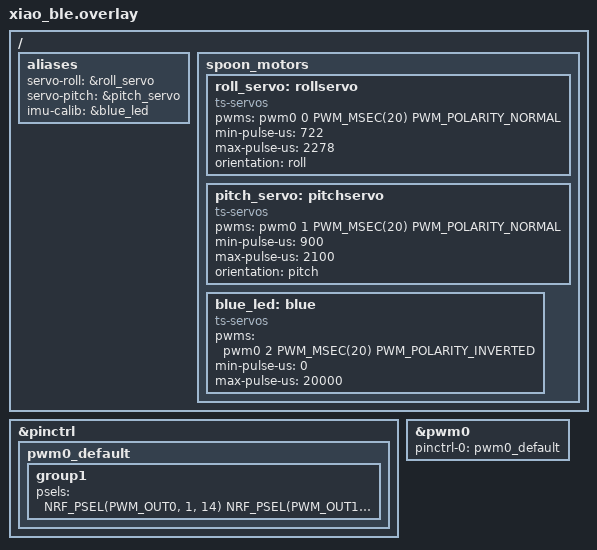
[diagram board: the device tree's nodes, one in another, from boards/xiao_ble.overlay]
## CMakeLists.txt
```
# SPDX-License-Identifier: Apache-2.0

cmake_minimum_required(VERSION 3.20.0)
find_package(Zephyr REQUIRED HINTS $ENV{ZEPHYR_BASE})
project(tremosense)

FILE(GLOB app_sources src/*.c)
target_sources(app PRIVATE ${app_sources})
target_include_directories(app PRIVATE include)
```

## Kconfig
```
source "Kconfig.zephyr"

config IMU_CALIBRATION_WHILE_TESTING
        bool "Enable calibration  of IMU at boot"
        default n
        help
                If enabled, the IMU collects 300 samples over span of 3 seconds 
                and averages values for all 6 measurments (accelerometer and 
                gyroscope in x,y,z axes)

config PWM_TEST_RB_LED
        bool "Enable PWM test for RB LED"
        default n
        help
                If enabled, the RB LED will be used for testing PWM feature. 
                Green LED indicates Roll Servo motor and Red LED indicates Pitch 
                Servo motor.

config CLEAR_SCREEN
        bool "Clear screen before printing next values"
        default n
        help
                If enabled, the console screen will be cleared before printing 
                upcoming IMU, EKK and servo values.
```

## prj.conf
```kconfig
CONFIG_STDOUT_CONSOLE=y
CONFIG_I2C=y
CONFIG_SPI=y
CONFIG_SENSOR=y
CONFIG_LSM6DSL_TRIGGER_GLOBAL_THREAD=y
CONFIG_CBPRINTF_FP_SUPPORT=y
CONFIG_LOG=y
CONFIG_LOG_MODE_DEFERRED=y
CONFIG_CBPRINTF_FP_SUPPORT=y
```

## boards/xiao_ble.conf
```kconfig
CONFIG_PWM=y
CONFIG_PWM_NRFX=y

CONFIG_LOG=y
CONFIG_LOG_MODE_DEFERRED=y
CONFIG_LOG_FMT_SECTION=y
CONFIG_STDOUT_CONSOLE=y
CONFIG_CBPRINTF_FP_SUPPORT=y

CONFIG_I2C=y
CONFIG_SENSOR=y
CONFIG_LSM6DSL_TRIGGER_OWN_THREAD=y
CONFIG_IMU_CALIBRATION_WHILE_TESTING=y
CONFIG_CLEAR_SCREEN=n
```

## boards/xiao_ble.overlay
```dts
&pinctrl {
        pwm0_default: pwm0_default {
                group1 {
                        psels = <NRF_PSEL(PWM_OUT0, 1, 14)  // D9  - Roll servo
                                 NRF_PSEL(PWM_OUT1, 1, 15)  // D10 - Pitch Servo
                                 NRF_PSEL(PWM_OUT2, 0, 06)>; // IMU Calibration
                };
        };
};

&pwm0 {
	status = "okay";
        /delete-property/ pinctrl-1;
	pinctrl-0 = <&pwm0_default>;
	pinctrl-names = "default";
};

/ {
        aliases {
                servo-roll = &roll_servo;
                servo-pitch = &pitch_servo;
                imu-calib = &blue_led;
        };
        spoon_motors {
                roll_servo: rollservo {
                        compatible = "ts-servos";
                        pwms = <&pwm0 0 PWM_MSEC(20) PWM_POLARITY_NORMAL>;
                        min-pulse-us = <722>;
                        max-pulse-us = <2278>;
                        orientation = "roll";
                };
                pitch_servo: pitchservo {
                        compatible = "ts-servos";
                        pwms = <&pwm0 1 PWM_MSEC(20) PWM_POLARITY_NORMAL>;
                        min-pulse-us = <900>;
                        max-pulse-us = <2100>;
                        orientation = "pitch";
                };
                blue_led: blue {                        
                        compatible = "ts-servos";
                        pwms = <&pwm0 2 PWM_MSEC(20) PWM_POLARITY_INVERTED>;
                        min-pulse-us = <0>;
                        max-pulse-us = <20000>;
                };
        };
};
```

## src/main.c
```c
#include "imu.h"
#include "pwm.h"
#include "ekf.h"

LOG_MODULE_REGISTER(main, LOG_LEVEL_INF);

static struct k_thread imu_thread_data;
static struct k_thread pwm_thread_data;

k_tid_t imu_tid, pwm_tid;

K_THREAD_STACK_DEFINE(imu_thread_stack, IMU_THREAD_STACK_SIZE_BYTES);
K_THREAD_STACK_DEFINE(pwm_thread_stack, PWM_TASK_STACK_SIZE_BYTES);


int main(void)
{
	int err;

	const struct device *const lsm6ds3_trc_dev = DEVICE_DT_GET_ONE(st_lsm6dsl);
	err = imu_init(lsm6ds3_trc_dev);
	if (err) {
		LOG_ERR("Failed to initialize IMU: %d", err);
		return err;
	}


	ekf_init();	

	imu_tid = k_thread_create(&imu_thread_data, 
				  imu_thread_stack,
				  K_THREAD_STACK_SIZEOF(imu_thread_stack),
				  (k_thread_entry_t)imu_thread_function,
				  NULL, NULL, NULL,
				  K_PRIO_PREEMPT(1), 0, K_NO_WAIT);
	
	pwm_tid = k_thread_create(&pwm_thread_data, 
				  pwm_thread_stack,
				  K_THREAD_STACK_SIZEOF(pwm_thread_stack),
				  (k_thread_entry_t)pwm_thread_function,
				  NULL, NULL, NULL,
				  K_PRIO_PREEMPT(5), 0, K_NO_WAIT);


	return 0;
}
```

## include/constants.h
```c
#ifndef CONSTANTS_H
#define CONSTANTS_H

/* EKF process noise covariance (Q).
 * Represents uncertainty in the gyroscope-based prediction model.
 * Higher values increase reliance on accelerometer corrections.
 */
#define Q_GYRO_PROCESS_NOISE 0.0f

/* EKF measurement noise covariance (R).
 * Represents uncertainty in accelerometer angle measurements.
 * Higher values increase reliance on gyroscope integration.
 */
#define R_ACCEL_MEASUREMENT_NOISE 0.0f

/* LQR Controller Gain :
 * Row 0 -> Roll servo controller gains
 * Row 1 -> Pitch servo controller gains
 *
 * Column 0 -> Roll angle gain
 * Column 1 -> Roll angular velocity gain
 * Column 2 -> Pitch angle gain
 * Column 3 -> Pitch angular velocity gain
 */
static const float K_lqr[2][4] = {
    { 0.0f, 0.0f, 0.0f, 0.0f }, 
    { 0.0f, 0.0f, 0.0f, 0.0f }  
};

/* Limit pitch estimate to avoid Euler-angle singularities
 * (tan(), sec()) near ±90°.
 */
#define MAX_PITCH_RAD 0.0f

#endif /* CONSTANTS_H */
```

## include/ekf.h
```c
#ifndef EKF_H
#define EKF_H

#include <zephyr/logging/log.h>
#include "constants.h"

typedef struct {
    float roll; 
    float pitch;
} ekf_result_t;

extern ekf_result_t ekf_calculated_results;

#define RAD_TO_DEG 57.2957795f

void ekf_init(void);

void ekf_update(float ax, float ay, float az,
                float gx, float gy, float gz,
                float dt, float Q_val, float R_val,
                ekf_result_t *result);

#endif /* EKF_H */
```

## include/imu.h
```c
#ifndef IMU_H
#define IMU_H

#include <zephyr/kernel.h>
#include <zephyr/device.h>
#include <zephyr/logging/log.h>
#include <zephyr/drivers/sensor.h>
#include <zephyr/devicetree.h>

#define IMU_SLEEP_MS 50
#define IMU_THREAD_STACK_SIZE_BYTES 2048

extern k_tid_t imu_tid;

void lsm6ds3_trc_trigger_handler(const struct device *dev,
			     const struct sensor_trigger *trig);

int imu_init(const struct device *imu_dev);

void calibrate_imu(void);

int imu_readings(void);

void imu_thread_function(void *arg1, void *arg2, void *arg3);

#endif /* IMU_H */
```

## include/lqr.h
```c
#ifndef LQR_H
#define LQR_H

#include "constants.h"

#define DEG_TO_RAD 0.01745329f
#define RAD_TO_DEG 57.2957795f

void lqr_update(float phi_deg, float theta_deg, 
                float p_raw, float q_raw, 
                float bias_phi, float bias_theta, 
                float *u_roll_deg, float *u_pitch_deg);

#endif /* LQR_H */
```

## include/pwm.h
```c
#ifndef PWM_H
#define PWM_H

#include "lqr.h"

#include <zephyr/kernel.h>
#include <zephyr/drivers/pwm.h>
#include <zephyr/logging/log.h>

#include "lqr.h"

extern const struct pwm_dt_spec roll;
extern const struct pwm_dt_spec pitch;

extern float target_servo_roll_deg, target_servo_pitch_deg;

#define PWM_TASK_STACK_SIZE_BYTES 1024

#define PWM_SLEEP_MS 10 

extern k_tid_t pwm_tid;

int servos_reset(void);

int set_servo_angle(const struct pwm_dt_spec *pwm_dev_roll, 
                   const struct pwm_dt_spec *pwm_dev_pitch,
                   lqr_result_t *result);

int servo_sweep(const struct pwm_dt_spec *pwm_dev);

void pwm_thread_function(void *arg1, void *arg2, void *arg3);

#endif /* PWM_H */
```

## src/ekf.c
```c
#include "ekf.h"

/* EKF State Vector
 *
 * x[0] -> Roll angle  (phi)   [rad]
 * x[1] -> Pitch angle (theta) [rad]
 *
 * The EKF estimates drift-free roll and pitch angles by
 * fusing gyroscope angular rates with accelerometer measurements.
 */

static float x[2];      
static float P[2][2];  

ekf_result_t ekf_calculated_results;

void ekf_init(void)
{
    x[0] = 0.0f; x[1] = 0.0f;
    P[0][0] = 0.1f; P[0][1] = 0.0f;
    P[1][0] = 0.0f; P[1][1] = 0.1f;
}

void ekf_update(float ax, float ay, float az,
                float gx, float gy, float gz,
                float dt, float Q_val, float R_val,
                ekf_result_t *result)
{
    float p = gx, q = gy, r = gz;

    float phi   = x[0];
    float theta = x[1];

    float s_phi = sinf(phi);
    float c_phi = cosf(phi);
    float s_the = sinf(theta);
    float c_the = cosf(theta);
    float t_the = s_the / c_the;

    float sec_the = (fabsf(c_the) < 0.01f) ? 100.0f : (1.0f / c_the);

    // PREDICT -----------------------------------------------------------------
    float phi_dot   = p + q * s_phi * t_the + r * c_phi * t_the;
    float theta_dot = q * c_phi - r * s_phi;

    x[0] += phi_dot   * dt;
    x[1] += theta_dot * dt;

    float A11 =  q * c_phi * t_the - r * s_phi * t_the;
    float A12 = (q * s_phi + r * c_phi) * (sec_the * sec_the);
    float A21 = -q * s_phi - r * c_phi;

    float F[2][2];
    F[0][0] = 1.0f + A11 * dt;
    F[0][1] =        A12 * dt;
    F[1][0] =        A21 * dt;
    F[1][1] = 1.0f;             // A22=0

    float tmp[2][2];
    tmp[0][0] = F[0][0]*P[0][0] + F[0][1]*P[1][0];
    tmp[0][1] = F[0][0]*P[0][1] + F[0][1]*P[1][1];
    tmp[1][0] = F[1][0]*P[0][0] + F[1][1]*P[1][0];
    tmp[1][1] = F[1][0]*P[0][1] + F[1][1]*P[1][1];

    P[0][0] = tmp[0][0]*F[0][0] + tmp[0][1]*F[0][1] + Q_val;
    P[0][1] = tmp[0][0]*F[1][0] + tmp[0][1]*F[1][1];
    P[1][0] = tmp[1][0]*F[0][0] + tmp[1][1]*F[0][1];
    P[1][1] = tmp[1][0]*F[1][0] + tmp[1][1]*F[1][1] + Q_val;

    // UPDATE ------------------------------------------------------------------
    float accel_roll  = atan2f(ay, az);
    float accel_pitch = atan2f(-ax, sqrtf(ay*ay + az*az));

    float y0 = accel_roll  - x[0];
    float y1 = accel_pitch - x[1];

    float S[2][2];
    S[0][0] = P[0][0] + R_val;
    S[0][1] = P[0][1];
    S[1][0] = P[1][0];
    S[1][1] = P[1][1] + R_val;

    float det_S = S[0][0]*S[1][1] - S[0][1]*S[1][0];
    float inv_S[2][2];
    inv_S[0][0] =  S[1][1] / det_S;
    inv_S[0][1] = -S[0][1] / det_S;
    inv_S[1][0] = -S[1][0] / det_S;
    inv_S[1][1] =  S[0][0] / det_S;

    float K[2][2];
    K[0][0] = P[0][0]*inv_S[0][0] + P[0][1]*inv_S[1][0];
    K[0][1] = P[0][0]*inv_S[0][1] + P[0][1]*inv_S[1][1];
    K[1][0] = P[1][0]*inv_S[0][0] + P[1][1]*inv_S[1][0];
    K[1][1] = P[1][0]*inv_S[0][1] + P[1][1]*inv_S[1][1];

    x[0] += K[0][0]*y0 + K[0][1]*y1;
    x[1] += K[1][0]*y0 + K[1][1]*y1;

    float IK[2][2];
    IK[0][0] = 1.0f - K[0][0]; IK[0][1] = -K[0][1];
    IK[1][0] = -K[1][0];       IK[1][1] = 1.0f - K[1][1];

    float Pn[2][2];
    Pn[0][0] = IK[0][0]*P[0][0] + IK[0][1]*P[1][0];
    Pn[0][1] = IK[0][0]*P[0][1] + IK[0][1]*P[1][1];
    Pn[1][0] = IK[1][0]*P[0][0] + IK[1][1]*P[1][0];
    Pn[1][1] = IK[1][0]*P[0][1] + IK[1][1]*P[1][1];
    P[0][0]=Pn[0][0]; P[0][1]=Pn[0][1];
    P[1][0]=Pn[1][0]; P[1][1]=Pn[1][1];

    if (x[1] > MAX_PITCH_RAD) {
        x[1] = MAX_PITCH_RAD;
    } else if (x[1] < -MAX_PITCH_RAD) {
        x[1] = -MAX_PITCH_RAD;
    }

    result->roll  = x[0] * RAD_TO_DEG;
    result->pitch = x[1] * RAD_TO_DEG;
}
```

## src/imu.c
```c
#include "imu.h"
#include "pwm.h"
#include "ekf.h"
#include "lqr.h"

#include <stdio.h>
#include <zephyr/sys/util.h>

LOG_MODULE_REGISTER(IMU, LOG_LEVEL_INF);

int print_samples = 0, lsm6ds3_trc_trig_cnt = 0, cnt = 0;
char out_str[128];

const struct pwm_dt_spec imu_calib_led = PWM_DT_SPEC_GET(DT_ALIAS(imu_calib));
#define IMU_CALIB_LED_MIN    PWM_USEC(DT_PROP(DT_ALIAS(imu_calib), min_pulse_us))
#define IMU_CALIB_LED_MAX    PWM_USEC(DT_PROP(DT_ALIAS(imu_calib), max_pulse_us))
#define IMU_CALIB_LED_PERIOD (IMU_CALIB_LED_MAX - IMU_CALIB_LED_MIN)

struct sensor_value accel_x_out, accel_y_out, accel_z_out;
struct sensor_value gyro_x_out, gyro_y_out, gyro_z_out;
float accel_offset_x = 0, accel_offset_y = 0, accel_offset_z = 0;
float gyro_offset_x = 0, gyro_offset_y = 0, gyro_offset_z = 0;

void lsm6ds3_trc_trigger_handler(const struct device *dev,
				    const struct sensor_trigger *trig)
{
	static struct sensor_value accel_x, accel_y, accel_z;
	static struct sensor_value gyro_x, gyro_y, gyro_z;

	lsm6ds3_trc_trig_cnt++;

	sensor_sample_fetch_chan(dev, SENSOR_CHAN_ACCEL_XYZ);
	sensor_channel_get(dev, SENSOR_CHAN_ACCEL_X, &accel_x);
	sensor_channel_get(dev, SENSOR_CHAN_ACCEL_Y, &accel_y);
	sensor_channel_get(dev, SENSOR_CHAN_ACCEL_Z, &accel_z);

	sensor_sample_fetch_chan(dev, SENSOR_CHAN_GYRO_XYZ);
	sensor_channel_get(dev, SENSOR_CHAN_GYRO_X, &gyro_x);
	sensor_channel_get(dev, SENSOR_CHAN_GYRO_Y, &gyro_y);
	sensor_channel_get(dev, SENSOR_CHAN_GYRO_Z, &gyro_z);

	accel_x_out = accel_x;
	accel_y_out = accel_y;
	accel_z_out = accel_z;

	gyro_x_out = gyro_x;
	gyro_y_out = gyro_y;
	gyro_z_out = gyro_z;

	k_sem_give(&imu_sem);
}

void calibrate_imu(void)
{
        int samples = 300;
        float sum_ax = 0, sum_ay = 0, sum_az = 0;
        float sum_gx = 0, sum_gy = 0, sum_gz = 0;

        LOG_INF("Please place the board flat on a table and DO NOT TOUCH IT.\n");

	uint32_t pulse = IMU_CALIB_LED_MAX;
	pwm_set_pulse_dt(&imu_calib_led, pulse);

        k_msleep(3000);
        LOG_INF("\n--- STARTING CALIBRATION ---\n");

        for (int i = 0; i < samples; i++) {
		print_samples = 1;
                sum_ax += sensor_value_to_float(&accel_x_out);
                sum_ay += sensor_value_to_float(&accel_y_out);
                sum_az += sensor_value_to_float(&accel_z_out);

                sum_gx += sensor_value_to_float(&gyro_x_out);
                sum_gy += sensor_value_to_float(&gyro_y_out);
                sum_gz += sensor_value_to_float(&gyro_z_out);

                k_msleep(10); 
        }

        gyro_offset_x = sum_gx / samples;
        gyro_offset_y = sum_gy / samples;
        gyro_offset_z = sum_gz / samples;

        accel_offset_x = sum_ax / samples;
        accel_offset_y = sum_ay / samples;
        accel_offset_z = (sum_az / samples) - 9.80665f; 

        LOG_INF("Calibration Complete! (5 seconds pause for user to check offset)\n");
        LOG_INF("Accel Offsets: X: %.3f, Y: %.3f, Z: %.3f\n", (double)accel_offset_x, (double)accel_offset_y, (double)accel_offset_z);
        LOG_INF("Gyro Offsets:  X: %.3f, Y: %.3f, Z: %.3f\n\n", (double)gyro_offset_x, (double)gyro_offset_y, (double)gyro_offset_z);
        
	uint32_t wait_start = k_uptime_get_32();
        while ((k_uptime_get_32() - wait_start) < 5000) {
		if(pulse == IMU_CALIB_LED_MAX)
			pulse = IMU_CALIB_LED_MIN;
		else
			pulse = IMU_CALIB_LED_MAX; 
		pwm_set_pulse_dt(&imu_calib_led, pulse);
                k_msleep(200); 
        }
}

int imu_init(const struct device *imu_dev)
{
	int err;
	struct sensor_trigger trig;
        struct sensor_value odr_attr, acc_full_scale, gyro_full_scale;

	trig.type = SENSOR_TRIG_DATA_READY;
	trig.chan = SENSOR_CHAN_ACCEL_XYZ;

	if (!device_is_ready(imu_dev)) {
		LOG_ERR("device not ready");
		return -EIO;
	}

	odr_attr.val1 = 208;
	odr_attr.val2 = 0;

	if ((err = sensor_attr_set(imu_dev, SENSOR_CHAN_ACCEL_XYZ,
			    SENSOR_ATTR_SAMPLING_FREQUENCY, &odr_attr)) < 0) {
		LOG_ERR("Cannot set sampling frequency for accel: %d", err);
		return err;
	}

	if ((err = sensor_attr_set(imu_dev, SENSOR_CHAN_GYRO_XYZ,
			    SENSOR_ATTR_SAMPLING_FREQUENCY, &odr_attr)) < 0) {
		LOG_ERR("Cannot set sampling frequency for gyro: %d", err);
		return err;
	}

	/* 16g accel measurment range FS */
        acc_full_scale.val1 = 156;
        acc_full_scale.val2 = 906400;
        
        if ((err = sensor_attr_set(imu_dev, SENSOR_CHAN_ACCEL_XYZ,
			    SENSOR_ATTR_FULL_SCALE, &acc_full_scale)) < 0) {
		LOG_ERR("Cannot set sampling frequency for accel: %d", err);
		return err;
	}

	/* 2000 dps gyro measurment range FS */
        gyro_full_scale.val1 = 34;
        gyro_full_scale.val2 = 906585;
        
        if ((err = sensor_attr_set(imu_dev, SENSOR_CHAN_GYRO_XYZ,
			    SENSOR_ATTR_FULL_SCALE, &gyro_full_scale)) < 0) {
		LOG_ERR("Cannot set sampling frequency for gyro: %d", err);
		return err;
	}

	if ((err = sensor_trigger_set(imu_dev, &trig, lsm6ds3_trc_trigger_handler)) != 0) {
		LOG_ERR("Could not set sensor type and channel: %d", err);
		return err;
	}

	if ((err = sensor_sample_fetch(imu_dev)) < 0) {
		LOG_ERR("Sensor sample update error: %d", err);
		return err;
	}

	#if CONFIG_IMU_CALIBRATION_WHILE_TESTING
		calibrate_imu();
	#endif

        return 0;
}

int imu_readings(void)
{
	#if CONFIG_CLEAR_SCREEN
		printk("\033[2J\033[H");
	#endif

	/* lsm6ds3_trc accel */
	snprintf(out_str, sizeof(out_str), "accel x:%f m/s2 y:%f m/s2 z:%f m/s2",
							(double)(sensor_value_to_float(&accel_x_out) - accel_offset_x),
							(double)(sensor_value_to_float(&accel_y_out) - accel_offset_y),
							(double)(sensor_value_to_float(&accel_z_out) - accel_offset_z));
	LOG_INF("%s\n", out_str);

	/* lsm6ds3_trc gyro */
	snprintf(out_str, sizeof(out_str), "gyro  x:%f dps  y:%f dps  z:%f dps ",
							(double)((sensor_value_to_float(&gyro_x_out)* RAD_TO_DEG) - gyro_offset_x* RAD_TO_DEG),
							(double)((sensor_value_to_float(&gyro_y_out)* RAD_TO_DEG) - gyro_offset_y* RAD_TO_DEG),
							(double)((sensor_value_to_float(&gyro_z_out)* RAD_TO_DEG) - gyro_offset_z* RAD_TO_DEG));
	LOG_INF("%s\n", out_str);

	LOG_INF("loop:%d trig_cnt:%d\n\n", ++cnt, lsm6ds3_trc_trig_cnt);


	return 0;
}

void imu_thread_function(const struct device *dev, void *arg2, void *arg3) {
	int err;

	uint32_t last_time = k_uptime_get_32();
	while (1) {
		 if (k_sem_take(&imu_sem, K_FOREVER) != 0) {
			printk("Input data not available!\n");
		} else {
			if ((err = imu_readings()) < 0) {
				LOG_ERR("Error reading IMU data: %d", err);
				k_thread_abort(imu_tid);
			}

			uint32_t current_time = k_uptime_get_32();
			float actual_dt_seconds = (float)(current_time - last_time) / 1000.0f;
			last_time = current_time;
			ekf_update(sensor_value_to_float(&accel_x_out) - accel_offset_x,
				   sensor_value_to_float(&accel_y_out) - accel_offset_y,
				   sensor_value_to_float(&accel_z_out) - accel_offset_z,
				   sensor_value_to_float(&gyro_x_out) - gyro_offset_x,
				   sensor_value_to_float(&gyro_y_out) - gyro_offset_y,
				   sensor_value_to_float(&gyro_z_out) - gyro_offset_z,
				   actual_dt_seconds, 
				   Q_GYRO_PROCESS_NOISE, 
				   R_ACCEL_MEASUREMENT_NOISE, 
				   &ekf_calculated_results);

			printk("Est. Roll: %.2f deg | Est. Pitch: %.2f deg\n\n",
			       (double)ekf_calculated_results.roll, 
			       (double)ekf_calculated_results.pitch);

			lqr_update(ekf_calculated_results.roll, 
				   ekf_calculated_results.pitch,
				   sensor_value_to_float(&gyro_x_out), 
				   sensor_value_to_float(&gyro_y_out), 
				   gyro_offset_x, 
				   gyro_offset_y);
		}
	}
}
```

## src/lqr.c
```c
#include "lqr.h"
#include "pwm.h"

/* LQR State Vector
 *
 * x_state[0] -> Roll angle            (phi)   [rad]
 * x_state[1] -> Roll angular velocity (p)     [rad/s]
 * x_state[2] -> Pitch angle           (theta) [rad]
 * x_state[3] -> Pitch angular velocity(q)     [rad/s]
 *
 * Roll and pitch angles are obtained from the EKF.
 * Roll and pitch rates are obtained directly from the gyroscope and used after 
 * bias correction.
 */

lqr_result_t obtained_lqr_values;

void lqr_update(float phi_deg, float theta_deg, 
                float p_raw, float q_raw, 
                float bias_phi, float bias_theta) 
{
    float phi_rad = phi_deg * DEG_TO_RAD;
    float theta_rad = theta_deg * DEG_TO_RAD;

    float p_clean = p_raw - bias_phi;
    float q_clean = q_raw - bias_theta;

    float x_state[4] = {phi_rad, p_clean, theta_rad, q_clean};

    float u_roll_rad  = -(K_lqr[0][0]*x_state[0] + K_lqr[0][1]*x_state[1] + 
                          K_lqr[0][2]*x_state[2] + K_lqr[0][3]*x_state[3]);
                          
    float u_pitch_rad = -(K_lqr[1][0]*x_state[0] + K_lqr[1][1]*x_state[1] + 
                          K_lqr[1][2]*x_state[2] + K_lqr[1][3]*x_state[3]);

    obtained_lqr_values.roll_to_servo  = -(u_roll_rad * RAD_TO_DEG) + 90.0f;
    obtained_lqr_values.pitch_to_servo = (u_pitch_rad * RAD_TO_DEG) + 90.0f;

    while (k_msgq_put(&lqr_res, &obtained_lqr_values, K_NO_WAIT) != 0) {
            k_msgq_purge(&lqr_res);
    }
}
```

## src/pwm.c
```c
#include "pwm.h"

LOG_MODULE_REGISTER(PWM, LOG_LEVEL_INF);

lqr_result_t lqr_val_to_servos;

const struct pwm_dt_spec roll = PWM_DT_SPEC_GET(DT_ALIAS(servo_roll));
const struct pwm_dt_spec pitch = PWM_DT_SPEC_GET(DT_ALIAS(servo_pitch));

#define ROLL_SERVO_MIN    PWM_USEC(DT_PROP(DT_ALIAS(servo_roll), min_pulse_us))
#define ROLL_SERVO_MAX    PWM_USEC(DT_PROP(DT_ALIAS(servo_roll), max_pulse_us))
#define ROLL_SERVO_PERIOD (ROLL_SERVO_MAX - ROLL_SERVO_MIN)

#define PITCH_SERVO_MIN    PWM_USEC(DT_PROP(DT_ALIAS(servo_pitch), min_pulse_us))
#define PITCH_SERVO_MAX    PWM_USEC(DT_PROP(DT_ALIAS(servo_pitch), max_pulse_us))
#define PITCH_SERVO_PERIOD (PITCH_SERVO_MAX - PITCH_SERVO_MIN)

int set_servo_angle(const struct pwm_dt_spec *pwm_dev_roll, 
                   const struct pwm_dt_spec *pwm_dev_pitch,
                   lqr_result_t *result)
{
	uint32_t err, pulse_roll = 0, pulse_pitch = 0;
	
	if (result->roll_to_servo > 180) 
		result->roll_to_servo = 180;
	if (result->pitch_to_servo > 180) 
		result->pitch_to_servo = 180;

	pulse_roll = ROLL_SERVO_MIN + ((ROLL_SERVO_PERIOD * result->roll_to_servo) / 180);
	if ((err = pwm_set_pulse_dt(pwm_dev_roll, pulse_roll)) < 0)
		return err;
	
	pulse_pitch = PITCH_SERVO_MIN + ((PITCH_SERVO_PERIOD * result->pitch_to_servo) / 180);
	if ((err = pwm_set_pulse_dt(pwm_dev_pitch, pulse_pitch)) < 0)
		return err;

    	return 0;
}

int servos_reset(void)
{
	uint32_t angle_roll = 90, angle_pitch = 90;
	uint32_t pulse_roll, pulse_pitch, err;

	pulse_roll = ROLL_SERVO_MIN + ((ROLL_SERVO_PERIOD * angle_roll) / 180);
	if ((err = pwm_set_pulse_dt(&roll, pulse_roll)) < 0)
		return err;
	
	pulse_pitch = PITCH_SERVO_MIN + ((PITCH_SERVO_PERIOD * angle_pitch) / 180);
	if ((err = pwm_set_pulse_dt(&pitch, pulse_pitch)) < 0)
		return err;

    	return 0;
}

int servo_sweep(const struct pwm_dt_spec *pwm_dev)
{
	uint32_t pulse = 0, ret = 0;

	for (uint32_t step = 0; step <= 360; step++) {
		uint32_t angle_deg = (step <= 180) ? step : (360 - step);
		if (pwm_dev == &roll)    
			pulse = ROLL_SERVO_MIN + ((ROLL_SERVO_PERIOD * angle_deg) / 180);
		else if (pwm_dev == &pitch)    
			pulse = PITCH_SERVO_MIN + ((PITCH_SERVO_PERIOD * angle_deg) / 180);

    		ret = pwm_set_pulse_dt(pwm_dev, pulse);
		if (ret != 0) {
			LOG_ERR("Error %d: failed to set pulse for angle %d\n", ret, angle_deg);
			return ret;
		}
		LOG_INF("Servo Angle set to: %d\n", angle_deg);
		#if CONFIG_PWM_TEST_RB_LED
			k_sleep(K_MSEC(1));
		#else
			k_sleep(K_MSEC(20));
		#endif
	}
	return 0;
}

void pwm_thread_function(void *arg1, void *arg2, void *arg3) {
	while(1) {
	#if CONFIG_PWM_TEST_RB_LED
		int err;
		if ((err = servo_sweep(&roll)) < 0) {
			LOG_ERR("Error sweeping roll servo: %d", err);
			k_thread_abort(pwm_tid);
		}

		k_sleep(K_MSEC(PWM_SLEEP_MS));

		if ((err = servo_sweep(&pitch)) < 0) {
			LOG_ERR("Error sweeping pitch servo: %d", err);
			k_thread_abort(pwm_tid);
		}

		k_sleep(K_MSEC(PWM_SLEEP_MS));
	#else
		k_msgq_get(&lqr_res, &lqr_val_to_servos, K_FOREVER);
		set_servo_angle(&roll, &pitch, &lqr_val_to_servos);

	#endif

	}
}
```
